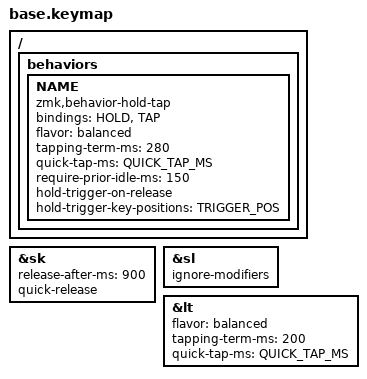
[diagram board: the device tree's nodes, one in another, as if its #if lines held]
#include <behaviors.dtsi>
#include <behaviors/unicode.dtsi> // Requires zmk-unicode module.
#include <zmk-helpers/helper.h> // Requires zmk-helpers module.
#include <dt-bindings/zmk/keys.h>
#ifdef CONFIG_WIRELESS
  #include <dt-bindings/zmk/bt.h>
  #include <dt-bindings/zmk/outputs.h>
  #define _BT_SEL_KEYS_                                                        \
      &bt BT_SEL 0 &bt BT_SEL 1 &bt BT_SEL 2 &bt BT_SEL 3 &bt BT_CLR
#else
  #define _BT_SEL_KEYS_ &trans &trans &trans &trans &trans
#endif

#define QWERTY 0
#define RAISE 1
#define LOWER 2
#define MOUSE 3

#define XXX &none
#define ___ &trans

/* Global defaults */

#define QUICK_TAP_MS 175

&sk {
  release-after-ms = <900>;
  quick-release;
};

&sl { // Allow sticky mods to chord across sticky layers.
  ignore-modifiers;
};

&lt {
  flavor = "balanced";
  tapping-term-ms = <200>;
  quick-tap-ms = <QUICK_TAP_MS>;
};

/* Homerow mods */

#define KEYS_L LT0 LT1 LT2 LT3 LT4 LM0 LM1 LM2 LM3 LM4 LB0 LB1 LB2 LB3 LB4
#define KEYS_R RT0 RT1 RT2 RT3 RT4 RM0 RM1 RM2 RM3 RM4 RB0 RB1 RB2 RB3 RB4
#ifndef LH2
  #define THUMBS LH1 LH0 RH0 RH1         // Thumbs on 34 keys.
#else
  #define THUMBS LH2 LH1 LH0 RH0 RH1 RH2 // Thumbs on 36+ keys.
#endif

#define MAKE_HRM(NAME, HOLD, TAP, TRIGGER_POS)                                 \
  ZMK_HOLD_TAP(NAME, bindings = <HOLD>, <TAP>; flavor = "balanced";            \
               tapping-term-ms = <280>; quick-tap-ms = <QUICK_TAP_MS>;         \
               require-prior-idle-ms = <150>; hold-trigger-on-release;         \
               hold-trigger-key-positions = <TRIGGER_POS>;)

MAKE_HRM(hml, &kp, &kp, KEYS_R THUMBS) // Left-hand HRMs.
MAKE_HRM(hmr, &kp, &kp, KEYS_L THUMBS) // Right-hand HRMs.

// Hack: Make HRM combos tap-only (cf, ZMK issue #544).
#define ZMK_COMBO_8(NAME, TAP, POS, LAYERS, COMBO_MS, IDLE_MS, HOLD, SIDE)     \
  MAKE_HRM(hm_combo_##NAME, &kp, TAP, SIDE THUMBS)                             \
  ZMK_COMBO_6(NAME, &hm_combo_##NAME HOLD 0, POS, LAYERS, COMBO_MS, IDLE_MS)

/* Combos, leader key sequences, mouse emulation */

#include "combos.dtsi" // Must be sourced after HRM-combo hack.
#include "leader.dtsi"
#include "mouse.dtsi"

// Smart-mouse, requires tri-state module.
ZMK_TRI_STATE(
    smart_mouse, bindings = <&tog MOUSE>, <&none>, <&tog MOUSE>;
    ignored-key-positions =
        <LT1 LT2 LH0 LH1 RT0 RT1 RT2 RT3 RM0 RM1 RM2 RM3 RH0 RH1>;
    ignored-layers = <MOUSE LOWER RAISE>;)

/* Keymap */

// ZMK_CONDITIONAL_LAYER(sys, FN NUM, SYS) // FN + NUM --> SYS.
//
#ifndef ZMK_BASE_LAYER
  #define ZMK_BASE_LAYER(name, LT, RT, LM, RM, LB, RB, LH, RH)                 \
      ZMK_LAYER(name, LT RT LM RM LB RB LH RH)
#endif

ZMK_BASE_LAYER(QWERTY,
&kp Q         &kp W        &kp E         &kp R         &kp T        ,   &kp Y         &kp U         &kp I         &kp O         &kp P         ,
&hml LCTRL A  &hml LALT S  &hml LGUI D   &hml LSHFT F  &kp G        ,   &kp H         &hmr RSHFT J  &hmr RGUI K   &hmr RALT L   &hmr RCTRL SEMI,
&kp Z         &kp X        &kp C         &kp V         &kp B        ,   &kp N         &kp M         &kp COMMA     &kp DOT       &kp SLASH     ,
                                         &lt LOWER TAB &kp BSPC     ,   &kp SPACE     &lt RAISE RET
 )

ZMK_BASE_LAYER(RAISE,
___           ___          ___           ___           ___          ,   &kp HOME      &kp PG_DN     &kp PG_UP     &kp END       &kp PSCRN     ,
&kp LCTRL     &kp LALT     &kp LGUI      &kp LSHFT     ___          ,   &kp LEFT      &kp DOWN      &kp UP        &kp RIGHT     &kp INS       ,
___           ___          ___           ___           ___          ,   ___           ___           ___           ___           ___           ,
                                         ___           &kp DEL      ,   ___           ___
 )

ZMK_BASE_LAYER(LOWER,
&kp F1        &kp F2       &kp F3        &kp F4        &kp KP_NUM   ,   &kp KP_PLUS   &kp KP_N7     &kp KP_N8     &kp KP_N9     &kp KP_MULTIPLY,
&kp F5        &kp F6       &kp F7        &kp F8        ___          ,   &kp KP_DOT    &kp KP_N4     &kp KP_N5     &kp KP_N6     &kp KP_N0     ,
&kp F9        &kp F10      &kp F11       &kp F12       ___          ,   &kp KP_MINUS  &kp KP_N1     &kp KP_N2     &kp KP_N3     &kp KP_DIVIDE ,
                                         ___           ___          ,   &kp KP_EQUAL  ___
 )

ZMK_BASE_LAYER(MOUSE,
                           _BT_SEL_KEYS_                            ,   U_WH_L        U_WH_D        U_WH_U        U_WH_R        XXX           ,
XXX           XXX          XXX           XXX           XXX          ,   U_MS_L        U_MS_D        U_MS_U        U_MS_R        XXX           ,
&bootloader   XXX          XXX           XXX           XXX          ,   XXX           XXX           XXX           XXX           &bootloader   ,
                                         ___           ___          ,   &mkp LCLK     &mkp RCLK
 )
/* vim: set ft=c tw=146: */
